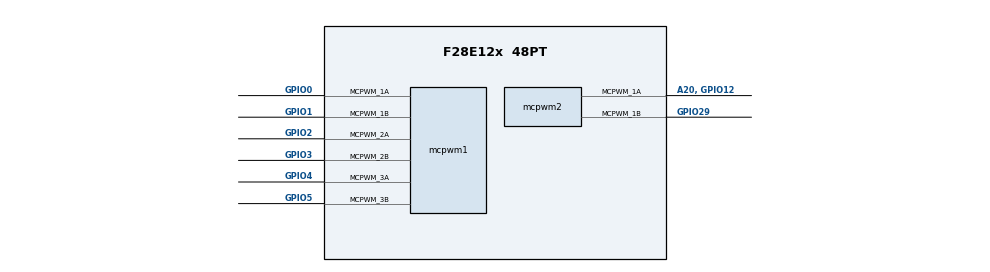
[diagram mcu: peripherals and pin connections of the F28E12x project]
/**
 * @cliArgs --device "F28E12x" --package "48PT" --part "F28E12x_48PT" --context "system" --product "C2000WARE@5.04.00.00"
 * @versions {"tool":"1.21.0+dev"}
 */

/**
 * Import the modules used in this configuration.
 */
const mcpwm  = scripting.addModule("/driverlib/mcpwm.js", {}, false);
const mcpwm1 = mcpwm.addInstance();
const mcpwm2 = mcpwm.addInstance();

/**
 * Write custom configuration values to the imported modules.
 */
mcpwm1.$name                                                         = "myMCPWM0";
mcpwm1.mcpwmTimebase_counterMode                                     = "MCPWM_COUNTER_MODE_UP_DOWN";
mcpwm1.mcpwmTimebase_period                                          = 4000;
mcpwm1.mcpwmCounterCompare_cmpA                                      = 2000;
mcpwm1.mcpwmActionQualifier_MCPWM_AQ_OUTPUT_1A_ON_TIMEBASE_UP_CMPA   = "MCPWM_AQ_OUTPUT_HIGH";
mcpwm1.mcpwmActionQualifier_MCPWM_AQ_OUTPUT_1A_ON_TIMEBASE_DOWN_CMPA = "MCPWM_AQ_OUTPUT_LOW";
mcpwm1.mcpwmActionQualifier_MCPWM_AQ_OUTPUT_2A_ON_TIMEBASE_UP_CMPA   = "MCPWM_AQ_OUTPUT_HIGH";
mcpwm1.mcpwmActionQualifier_MCPWM_AQ_OUTPUT_2A_ON_TIMEBASE_DOWN_CMPA = "MCPWM_AQ_OUTPUT_LOW";
mcpwm1.mcpwmActionQualifier_MCPWM_AQ_OUTPUT_3A_ON_TIMEBASE_UP_CMPA   = "MCPWM_AQ_OUTPUT_HIGH";
mcpwm1.mcpwmActionQualifier_MCPWM_AQ_OUTPUT_3A_ON_TIMEBASE_DOWN_CMPA = "MCPWM_AQ_OUTPUT_LOW";
mcpwm1.mcpwmCounterCompare_cmpA_pwm2                                 = 2000;
mcpwm1.mcpwmCounterCompare_cmpA_pwm3                                 = 2000;
mcpwm1.mcpwmDeadband_enableRED                                       = true;
mcpwm1.mcpwmDeadband_enableFED                                       = true;
mcpwm1.mcpwmDeadband_delayRED                                        = 100;
mcpwm1.mcpwmDeadband_delayFED                                        = 100;
mcpwm1.mcpwm.$assign                                                 = "MCPWM1";
mcpwm1.mcpwm.mcpwm_1aPin.$assign                                     = "GPIO0";
mcpwm1.mcpwm.mcpwm_1bPin.$assign                                     = "GPIO1";
mcpwm1.mcpwm.mcpwm_2aPin.$assign                                     = "GPIO2";
mcpwm1.mcpwm.mcpwm_2bPin.$assign                                     = "GPIO3";
mcpwm1.mcpwm.mcpwm_3aPin.$assign                                     = "GPIO4";
mcpwm1.mcpwm.mcpwm_3bPin.$assign                                     = "GPIO5";

mcpwm2.$name                                                         = "myMCPWM1";
mcpwm2.useCase                                                       = "2CH";
mcpwm2.mcpwmTimebase_period                                          = 4000;
mcpwm2.mcpwmTimebase_counterMode                                     = "MCPWM_COUNTER_MODE_UP_DOWN";
mcpwm2.mcpwmCounterCompare_cmpA                                      = 2000;
mcpwm2.mcpwmActionQualifier_MCPWM_AQ_OUTPUT_1A_ON_TIMEBASE_UP_CMPA   = "MCPWM_AQ_OUTPUT_HIGH";
mcpwm2.mcpwmActionQualifier_MCPWM_AQ_OUTPUT_1A_ON_TIMEBASE_DOWN_CMPA = "MCPWM_AQ_OUTPUT_LOW";
mcpwm2.mcpwm.$assign                                                 = "MCPWM3";
mcpwm2.mcpwm.mcpwm_1aPin.$assign                                     = "A20, GPIO12";
mcpwm2.mcpwm.mcpwm_1bPin.$assign                                     = "GPIO29";
